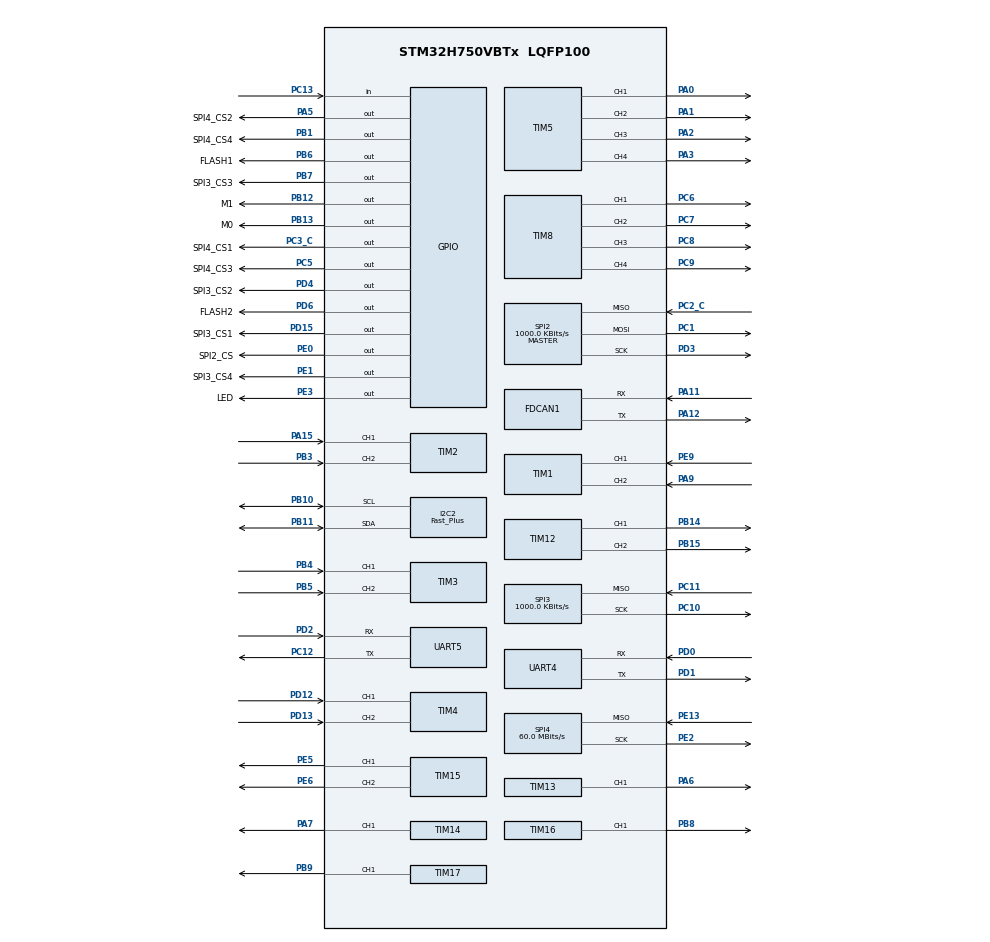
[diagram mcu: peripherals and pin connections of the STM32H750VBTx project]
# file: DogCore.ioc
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CORTEX_M7.default_mode_Activation=1
Dma.Request0=UART4_RX
Dma.Request1=UART4_TX
Dma.Request2=UART5_RX
Dma.Request3=UART5_TX
Dma.UART4_RX.0.Direction=DMA_PERIPH_TO_MEMORY
Dma.UART4_RX.0.EventEnable=DISABLE
Dma.UART4_RX.0.FIFOMode=DMA_FIFOMODE_DISABLE
Dma.UART4_RX.0.Instance=DMA1_Stream0
Dma.UART4_RX.0.MemDataAlignment=DMA_MDATAALIGN_BYTE
Dma.UART4_RX.0.MemInc=DMA_MINC_ENABLE
Dma.UART4_RX.0.Mode=DMA_NORMAL
Dma.UART4_RX.0.PeriphDataAlignment=DMA_PDATAALIGN_BYTE
Dma.UART4_RX.0.PeriphInc=DMA_PINC_DISABLE
Dma.UART4_RX.0.Polarity=HAL_DMAMUX_REQ_GEN_RISING
Dma.UART4_RX.0.Priority=DMA_PRIORITY_LOW
Dma.UART4_RX.0.RequestNumber=1
Dma.UART4_RX.0.SignalID=NONE
Dma.UART4_RX.0.SyncEnable=DISABLE
Dma.UART4_RX.0.SyncPolarity=HAL_DMAMUX_SYNC_NO_EVENT
Dma.UART4_RX.0.SyncRequestNumber=1
Dma.UART4_RX.0.SyncSignalID=NONE
Dma.UART4_TX.1.Direction=DMA_MEMORY_TO_PERIPH
Dma.UART4_TX.1.EventEnable=DISABLE
Dma.UART4_TX.1.FIFOMode=DMA_FIFOMODE_DISABLE
Dma.UART4_TX.1.Instance=DMA1_Stream1
Dma.UART4_TX.1.MemDataAlignment=DMA_MDATAALIGN_BYTE
Dma.UART4_TX.1.MemInc=DMA_MINC_ENABLE
Dma.UART4_TX.1.Mode=DMA_NORMAL
Dma.UART4_TX.1.PeriphDataAlignment=DMA_PDATAALIGN_BYTE
Dma.UART4_TX.1.PeriphInc=DMA_PINC_DISABLE
Dma.UART4_TX.1.Polarity=HAL_DMAMUX_REQ_GEN_RISING
Dma.UART4_TX.1.Priority=DMA_PRIORITY_LOW
Dma.UART4_TX.1.RequestNumber=1
Dma.UART4_TX.1.SignalID=NONE
Dma.UART4_TX.1.SyncEnable=DISABLE
Dma.UART4_TX.1.SyncPolarity=HAL_DMAMUX_SYNC_NO_EVENT
Dma.UART4_TX.1.SyncRequestNumber=1
Dma.UART4_TX.1.SyncSignalID=NONE
Dma.UART5_RX.2.Direction=DMA_PERIPH_TO_MEMORY
Dma.UART5_RX.2.EventEnable=DISABLE
Dma.UART5_RX.2.FIFOMode=DMA_FIFOMODE_DISABLE
Dma.UART5_RX.2.Instance=DMA1_Stream2
Dma.UART5_RX.2.MemDataAlignment=DMA_MDATAALIGN_BYTE
Dma.UART5_RX.2.MemInc=DMA_MINC_ENABLE
Dma.UART5_RX.2.Mode=DMA_NORMAL
Dma.UART5_RX.2.PeriphDataAlignment=DMA_PDATAALIGN_BYTE
Dma.UART5_RX.2.PeriphInc=DMA_PINC_DISABLE
Dma.UART5_RX.2.Polarity=HAL_DMAMUX_REQ_GEN_RISING
Dma.UART5_RX.2.Priority=DMA_PRIORITY_LOW
Dma.UART5_RX.2.RequestNumber=1
Dma.UART5_RX.2.SignalID=NONE
Dma.UART5_RX.2.SyncEnable=DISABLE
Dma.UART5_RX.2.SyncPolarity=HAL_DMAMUX_SYNC_NO_EVENT
Dma.UART5_RX.2.SyncRequestNumber=1
Dma.UART5_RX.2.SyncSignalID=NONE
Dma.UART5_TX.3.Direction=DMA_MEMORY_TO_PERIPH
Dma.UART5_TX.3.EventEnable=DISABLE
Dma.UART5_TX.3.FIFOMode=DMA_FIFOMODE_DISABLE
Dma.UART5_TX.3.Instance=DMA1_Stream3
Dma.UART5_TX.3.MemDataAlignment=DMA_MDATAALIGN_BYTE
Dma.UART5_TX.3.MemInc=DMA_MINC_ENABLE
Dma.UART5_TX.3.Mode=DMA_NORMAL
Dma.UART5_TX.3.PeriphDataAlignment=DMA_PDATAALIGN_BYTE
Dma.UART5_TX.3.PeriphInc=DMA_PINC_DISABLE
Dma.UART5_TX.3.Polarity=HAL_DMAMUX_REQ_GEN_RISING
Dma.UART5_TX.3.Priority=DMA_PRIORITY_LOW
Dma.UART5_TX.3.RequestNumber=1
Dma.UART5_TX.3.SignalID=NONE
Dma.UART5_TX.3.SyncEnable=DISABLE
Dma.UART5_TX.3.SyncPolarity=HAL_DMAMUX_SYNC_NO_EVENT
Dma.UART5_TX.3.SyncRequestNumber=1
Dma.UART5_TX.3.SyncSignalID=NONE
FDCAN1.AutoRetransmission=ENABLE
FDCAN1.CalculateBaudRateNominal=500000
FDCAN1.CalculateTimeBitNominal=2000
FDCAN1.CalculateTimeQuantumNominal=400.0
FDCAN1.NominalPrescaler=10
FDCAN1.NominalSyncJumpWidth=1
FDCAN1.NominalTimeSeg1=3
FDCAN1.NominalTimeSeg2=1
FDCAN1.TxBuffersNbr=32
FREERTOS.BinarySemaphores01=CAN_TX_BS,Static,CAN_TX_BSControlBlock,Available;UART_RX_BS,Static,UART_RX_BSControlBlock,Available
FREERTOS.CountingSemaphores01=UART_TX_CS,16,Static,UART_TX_CSControlBlock,0
FREERTOS.Mutexes01=IIC_LOCK,Static,IIC_LOCKControlBlock
FREERTOS.Queues01=KEY_CMD_Q,16,App_Key_EventPacket_t,0,Static,KEY_CMD_QBuffer,KEY_CMD_QControlBlock;UART_RX_Q,16,uint8_t,0,Static,UART_RX_QBuffer,UART_RX_QControlBlock;UART_TX_Q,16,APP_TxFrame_t,0,Static,UART_TX_QBuffer,UART_TX_QControlBlock;CAN_RXF0_Q,16,BSP_CAN_Packet_t,0,Static,CAN_RXF0_QBuffer,CAN_RXF0_QControlBlock;CAN_RXF1_Q,16,BSP_CAN_Packet_t,0,Static,CAN_RXF1_QBuffer,CAN_RXF1_QControlBlock
FREERTOS.Tasks01=defaultTask,8,128,StartDefaultTask,As weak,NULL,Static,defaultTaskBuffer,defaultTaskControlBlock;KEY_Debounce_T,52,128,Task_KEY_Debounce,As weak,NULL,Static,KEY_Debounce_TBuffer,KEY_Debounce_TControlBlock;KEY_CMD_T,44,128,TASK_KEY_CMD,As weak,NULL,Static,KEY_CMD_TBuffer,KEY_CMD_TControlBlock;UART_RX_T,51,256,Task_UART_RX,As weak,NULL,Static,UART_RX_TBuffer,UART_RX_TControlBlock;UART_TX_T,38,128,Task_UART_TX,As weak,NULL,Static,UART_TX_TBuffer,UART_TX_TControlBlock;UART_RX_CMD,50,128,Task_UART_RX_CMD,As weak,NULL,Static,UART_RX_CMDBuffer,UART_RX_CMDControlBlock;CAN_TX_T,37,128,Task_CAN_TX,As weak,NULL,Static,CAN_TX_TBuffer,CAN_TX_TControlBlock;CAN_RXF0_T,54,256,Task_CAN_RXF0,As weak,NULL,Static,CAN_RXF0_TBuffer,CAN_RXF0_TControlBlock;CAN_RXF1_T,53,256,Task_CAN_RXF1,As weak,NULL,Static,CAN_RXF1_TBuffer,CAN_RXF1_TControlBlock;Servo_T,46,128,Task_Servo,As weak,NULL,Static,Servo_TBuffer,Servo_TControlBlock;OLED_T,14,256,Task_OLED,As weak,NULL,Static,OLED_TBuffer,OLED_TControlBlock;Motion_T,45,256,Task_Motion,As weak,NULL,Static,Motion_TBuffer,Motion_TControlBlock;Motor_T,45,256,Task_Motor,As weak,NULL,Static,Motor_TBuffer,Motor_TControlBlock
FREERTOS.configMINIMAL_STACK_SIZE=64
FREERTOS.configTOTAL_HEAP_SIZE=256
I2C2.I2C_Speed_Mode=I2C_Fast_Plus
I2C2.Timing=0x0050174F
Mcu.Family=STM32H7
Mcu.Name=STM32H750VBTx
Mcu.Package=LQFP100
NVIC.DMA1_Stream0_IRQn=true\:5\:0\:false\:false\:true\:true\:false\:true\:true
NVIC.DMA1_Stream1_IRQn=true\:5\:0\:false\:false\:true\:true\:false\:true\:true
NVIC.DMA1_Stream2_IRQn=true\:5\:0\:false\:false\:true\:true\:false\:true\:true
NVIC.DMA1_Stream3_IRQn=true\:5\:0\:false\:false\:true\:true\:false\:true\:true
NVIC.FDCAN1_IT0_IRQn=true\:5\:0\:false\:false\:true\:true\:true\:true\:true
NVIC.FDCAN1_IT1_IRQn=true\:5\:0\:false\:false\:true\:true\:true\:true\:true
NVIC.PriorityGroup=NVIC_PRIORITYGROUP_4
NVIC.TIM6_DAC_IRQn=true\:15\:0\:false\:false\:true\:false\:false\:true\:true
NVIC.TimeBase=TIM6_DAC_IRQn
NVIC.TimeBaseIP=TIM6
NVIC.UART4_IRQn=true\:5\:0\:false\:false\:true\:true\:true\:true\:true
NVIC.UART5_IRQn=true\:5\:0\:false\:false\:true\:true\:true\:true\:true
PA0.Signal=S_TIM5_CH1
PA1.Signal=S_TIM5_CH2
PA11.Mode=FDCAN_Activate
PA11.Signal=FDCAN1_RX
PA12.Mode=FDCAN_Activate
PA12.Signal=FDCAN1_TX
PA13\ (JTMS/SWDIO).Mode=Serial_Wire
PA13\ (JTMS/SWDIO).Signal=DEBUG_JTMS-SWDIO
PA14\ (JTCK/SWCLK).Mode=Serial_Wire
PA14\ (JTCK/SWCLK).Signal=DEBUG_JTCK-SWCLK
PA15\ (JTDI).Signal=S_TIM2_CH1_ETR
PA2.Signal=S_TIM5_CH3
PA3.Signal=S_TIM5_CH4
PA5.GPIO_Label=SPI4_CS2
PA5.Signal=GPIO_Output
PA6.Signal=S_TIM13_CH1
PA7.Signal=S_TIM14_CH1
PA9.Signal=S_TIM1_CH2
PB1.GPIO_Label=SPI4_CS4
PB1.Signal=GPIO_Output
PB10.Mode=I2C
PB10.Signal=I2C2_SCL
PB11.Mode=I2C
PB11.Signal=I2C2_SDA
PB12.GPIO_Label=M1
PB12.GPIO_PuPd=GPIO_PULLDOWN
PB12.Signal=GPIO_Output
PB13.GPIO_Label=M0
PB13.GPIO_PuPd=GPIO_PULLDOWN
PB13.PinState=GPIO_PIN_RESET
PB13.Signal=GPIO_Output
PB14.Signal=S_TIM12_CH1
PB15.Signal=S_TIM12_CH2
PB3\ (JTDO/TRACESWO).Signal=S_TIM2_CH2
PB4\ (NJTRST).Signal=S_TIM3_CH1
PB5.Signal=S_TIM3_CH2
PB6.GPIO_Label=FLASH1
PB6.Signal=GPIO_Output
PB7.GPIO_Label=SPI3_CS3
PB7.Signal=GPIO_Output
PB8.Signal=S_TIM16_CH1
PB9.Signal=S_TIM17_CH1
PC1.Mode=Full_Duplex_Master
PC1.Signal=SPI2_MOSI
PC10.Mode=RX_Only_Simplex_Unidirect_Master
PC10.Signal=SPI3_SCK
PC11.Mode=RX_Only_Simplex_Unidirect_Master
PC11.Signal=SPI3_MISO
PC12.Mode=Asynchronous
PC12.Signal=UART5_TX
PC13.GPIO_PuPd=GPIO_PULLDOWN
PC13.Signal=GPIO_Input
PC2_C.Mode=Full_Duplex_Master
PC2_C.Signal=SPI2_MISO
PC3_C.GPIO_Label=SPI4_CS1
PC3_C.Signal=GPIO_Output
PC5.GPIO_Label=SPI4_CS3
PC5.Signal=GPIO_Output
PC6.Signal=S_TIM8_CH1
PC7.Signal=S_TIM8_CH2
PC8.Signal=S_TIM8_CH3
PC9.Signal=S_TIM8_CH4
PD0.Mode=Asynchronous
PD0.Signal=UART4_RX
PD1.Mode=Asynchronous
PD1.Signal=UART4_TX
PD12.Signal=S_TIM4_CH1
PD13.Signal=S_TIM4_CH2
PD15.GPIO_Label=SPI3_CS1
PD15.Signal=GPIO_Output
PD2.Mode=Asynchronous
PD2.Signal=UART5_RX
PD3.Mode=Full_Duplex_Master
PD3.Signal=SPI2_SCK
PD4.GPIO_Label=SPI3_CS2
PD4.Signal=GPIO_Output
PD6.GPIO_Label=FLASH2
PD6.Signal=GPIO_Output
PE0.GPIO_Label=SPI2_CS
PE0.Signal=GPIO_Output
PE1.GPIO_Label=SPI3_CS4
PE1.Signal=GPIO_Output
PE13.Mode=RX_Only_Simplex_Unidirect_Master
PE13.Signal=SPI4_MISO
PE2.Mode=RX_Only_Simplex_Unidirect_Master
PE2.Signal=SPI4_SCK
PE3.GPIO_Label=LED
PE3.Signal=GPIO_Output
PE5.Signal=S_TIM15_CH1
PE6.Signal=S_TIM15_CH2
PE9.Signal=S_TIM1_CH1
PH0-OSC_IN\ (PH0).Mode=HSE-External-Oscillator
PH0-OSC_IN\ (PH0).Signal=RCC_OSC_IN
PH1-OSC_OUT\ (PH1).Mode=HSE-External-Oscillator
PH1-OSC_OUT\ (PH1).Signal=RCC_OSC_OUT
ProjectManager.HeapSize=0x200
ProjectManager.StackSize=0x400
ProjectManager.TargetToolchain=CMake
RCC.ADCFreq_Value=50390625
RCC.APB1Freq_Value=120000000
RCC.APB2Freq_Value=120000000
RCC.APB3Freq_Value=120000000
RCC.APB4Freq_Value=120000000
RCC.CortexFreq_Value=480000000
RCC.D1PPRE=RCC_APB3_DIV2
RCC.D2PPRE1=RCC_APB1_DIV2
RCC.D2PPRE2=RCC_APB2_DIV2
RCC.D3PPRE=RCC_APB4_DIV2
RCC.DIVM1=5
RCC.DIVN1=192
RCC.DIVQ1=3
RCC.FDCANCLockSelection=RCC_FDCANCLKSOURCE_HSE
RCC.HCLKFreq_Value=240000000
RCC.HPRE=RCC_HCLK_DIV2
RCC.PLL2FRACN=0
RCC.PLL3FRACN=0
RCC.PLLFRACN=0
RCC.PLLSourceVirtual=RCC_PLLSOURCE_HSE
RCC.SPI123CLockSelection=RCC_SPI123CLKSOURCE_CLKP
RCC.SYSCLKFreq_VALUE=480000000
RCC.SYSCLKSource=RCC_SYSCLKSOURCE_PLLCLK
RCC.USBFreq_Value=320000000
SH.S_TIM12_CH1.0=TIM12_CH1,PWM Generation1 CH1
SH.S_TIM12_CH2.0=TIM12_CH2,PWM Generation2 CH2
SH.S_TIM13_CH1.0=TIM13_CH1,PWM Generation1 CH1
SH.S_TIM14_CH1.0=TIM14_CH1,PWM Generation1 CH1
SH.S_TIM15_CH1.0=TIM15_CH1,PWM Generation1 CH1
SH.S_TIM15_CH2.0=TIM15_CH2,PWM Generation2 CH2
SH.S_TIM16_CH1.0=TIM16_CH1,PWM Generation1 CH1
SH.S_TIM17_CH1.0=TIM17_CH1,PWM Generation1 CH1
SH.S_TIM1_CH1.0=TIM1_CH1,Encoder_Interface
SH.S_TIM1_CH2.0=TIM1_CH2,Encoder_Interface
SH.S_TIM2_CH1_ETR.0=TIM2_CH1,Encoder_Interface
SH.S_TIM2_CH2.0=TIM2_CH2,Encoder_Interface
SH.S_TIM3_CH1.0=TIM3_CH1,Encoder_Interface
SH.S_TIM3_CH2.0=TIM3_CH2,Encoder_Interface
SH.S_TIM4_CH1.0=TIM4_CH1,Encoder_Interface
SH.S_TIM4_CH2.0=TIM4_CH2,Encoder_Interface
SH.S_TIM5_CH1.0=TIM5_CH1,PWM Generation1 CH1
SH.S_TIM5_CH2.0=TIM5_CH2,PWM Generation2 CH2
SH.S_TIM5_CH3.0=TIM5_CH3,PWM Generation3 CH3
SH.S_TIM5_CH4.0=TIM5_CH4,PWM Generation4 CH4
SH.S_TIM8_CH1.0=TIM8_CH1,PWM Generation1 CH1
SH.S_TIM8_CH2.0=TIM8_CH2,PWM Generation2 CH2
SH.S_TIM8_CH3.0=TIM8_CH3,PWM Generation3 CH3
SH.S_TIM8_CH4.0=TIM8_CH4,PWM Generation4 CH4
SPI2.BaudRatePrescaler=SPI_BAUDRATEPRESCALER_64
SPI2.CalculateBaudRate=1000.0 KBits/s
SPI2.Direction=SPI_DIRECTION_2LINES
SPI2.Mode=SPI_MODE_MASTER
SPI2.VirtualType=VM_MASTER
SPI3.BaudRatePrescaler=SPI_BAUDRATEPRESCALER_64
SPI3.CalculateBaudRate=1000.0 KBits/s
SPI3.Direction=SPI_DIRECTION_2LINES_RXONLY
SPI3.Mode=SPI_MODE_MASTER
SPI3.VirtualType=VM_MASTER
SPI4.CalculateBaudRate=60.0 MBits/s
SPI4.Direction=SPI_DIRECTION_2LINES_RXONLY
SPI4.Mode=SPI_MODE_MASTER
SPI4.VirtualType=VM_MASTER
TIM1.EncoderMode=TIM_ENCODERMODE_TI12
TIM1.IC1Filter=10
TIM1.IC2Filter=10
TIM12.Channel-PWM\ Generation1\ CH1=TIM_CHANNEL_1
TIM12.Channel-PWM\ Generation2\ CH2=TIM_CHANNEL_2
TIM13.Channel=TIM_CHANNEL_1
TIM14.Channel=TIM_CHANNEL_1
TIM15.Channel-PWM\ Generation1\ CH1=TIM_CHANNEL_1
TIM15.Channel-PWM\ Generation2\ CH2=TIM_CHANNEL_2
TIM16.Channel=TIM_CHANNEL_1
TIM17.Channel=TIM_CHANNEL_1
TIM2.EncoderMode=TIM_ENCODERMODE_TI12
TIM2.IC1Filter=10
TIM2.IC2Filter=10
TIM3.EncoderMode=TIM_ENCODERMODE_TI12
TIM3.IC1Filter=10
TIM3.IC2Filter=10
TIM4.EncoderMode=TIM_ENCODERMODE_TI12
TIM4.IC1Filter=10
TIM4.IC2Filter=10
TIM5.Channel-PWM\ Generation1\ CH1=TIM_CHANNEL_1
TIM5.Channel-PWM\ Generation2\ CH2=TIM_CHANNEL_2
TIM5.Channel-PWM\ Generation3\ CH3=TIM_CHANNEL_3
TIM5.Channel-PWM\ Generation4\ CH4=TIM_CHANNEL_4
TIM8.Channel-PWM\ Generation1\ CH1=TIM_CHANNEL_1
TIM8.Channel-PWM\ Generation2\ CH2=TIM_CHANNEL_2
TIM8.Channel-PWM\ Generation3\ CH3=TIM_CHANNEL_3
TIM8.Channel-PWM\ Generation4\ CH4=TIM_CHANNEL_4
VP_FREERTOS_VS_CMSIS_V2.Mode=CMSIS_V2
VP_MEMORYMAP_VS_MEMORYMAP.Mode=CurAppReg
VP_SYS_VS_tim6.Mode=TIM6
VP_TIM12_VS_ClockSourceINT.Mode=Internal
VP_TIM13_VS_ClockSourceINT.Mode=Enable_Timer
VP_TIM14_VS_ClockSourceINT.Mode=Enable_Timer
VP_TIM15_VS_ClockSourceINT.Mode=Internal
VP_TIM16_VS_ClockSourceINT.Mode=Enable_Timer
VP_TIM17_VS_ClockSourceINT.Mode=Enable_Timer
VP_TIM5_VS_ClockSourceINT.Mode=Internal
VP_TIM8_VS_ClockSourceINT.Mode=Internal
board=custom

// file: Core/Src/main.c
/* USER CODE BEGIN Header */
/**
  ******************************************************************************
  * @file           : main.c
  * @brief          : Main program body
  ******************************************************************************
  * @attention
  *
  * Copyright (c) 2026 STMicroelectronics.
  * All rights reserved.
  *
  * This software is licensed under terms that can be found in the LICENSE file
  * in the root directory of this software component.
  * If no LICENSE file comes with this software, it is provided AS-IS.
  *
  ******************************************************************************
  */
/* USER CODE END Header */
#include "main.h"
#include "cmsis_os.h"
#include "dma.h"
#include "fdcan.h"
#include "i2c.h"
#include "spi.h"
#include "tim.h"
#include "usart.h"
#include "gpio.h"

void SystemClock_Config(void);
void PeriphCommonClock_Config(void);
static void MPU_Config(void);
void MX_FREERTOS_Init(void);

int main(void)
{

  /* MPU Configuration--------------------------------------------------------*/
  MPU_Config();

  /* MCU Configuration--------------------------------------------------------*/

  /* Reset of all peripherals, Initializes the Flash interface and the Systick. */
  HAL_Init();

  /* Configure the system clock */
  SystemClock_Config();

  /* Configure the peripherals common clocks */
  PeriphCommonClock_Config();

  /* Initialize all configured peripherals */
  MX_GPIO_Init();
  MX_DMA_Init();
  MX_TIM1_Init();
  MX_FDCAN1_Init();
  MX_TIM2_Init();
  MX_TIM3_Init();
  MX_TIM4_Init();
  MX_TIM5_Init();
  MX_TIM8_Init();
  MX_TIM12_Init();
  MX_TIM13_Init();
  MX_TIM14_Init();
  MX_TIM15_Init();
  MX_TIM16_Init();
  MX_TIM17_Init();
  MX_I2C2_Init();
  MX_SPI2_Init();
  MX_SPI3_Init();
  MX_SPI4_Init();
  MX_UART4_Init();
  MX_UART5_Init();

  /* Init scheduler */
  osKernelInitialize();  /* Call init function for freertos objects (in cmsis_os2.c) */
  MX_FREERTOS_Init();

  /* Start scheduler */
  osKernelStart();

  /* We should never get here as control is now taken by the scheduler */

  /* Infinite loop */
  while (1)
  {

  }
}

void SystemClock_Config(void)
{
  RCC_OscInitTypeDef RCC_OscInitStruct = {0};
  RCC_ClkInitTypeDef RCC_ClkInitStruct = {0};

  /** Supply configuration update enable
  */
  HAL_PWREx_ConfigSupply(PWR_LDO_SUPPLY);

  /** Configure the main internal regulator output voltage
  */
  __HAL_PWR_VOLTAGESCALING_CONFIG(PWR_REGULATOR_VOLTAGE_SCALE0);

  while(!__HAL_PWR_GET_FLAG(PWR_FLAG_VOSRDY)) {}

  /** Initializes the RCC Oscillators according to the specified parameters
  * in the RCC_OscInitTypeDef structure.
  */
  RCC_OscInitStruct.OscillatorType = RCC_OSCILLATORTYPE_HSI|RCC_OSCILLATORTYPE_HSE;
  RCC_OscInitStruct.HSEState = RCC_HSE_ON;
  RCC_OscInitStruct.HSIState = RCC_HSI_DIV1;
  RCC_OscInitStruct.HSICalibrationValue = RCC_HSICALIBRATION_DEFAULT;
  RCC_OscInitStruct.PLL.PLLState = RCC_PLL_ON;
  RCC_OscInitStruct.PLL.PLLSource = RCC_PLLSOURCE_HSE;
  RCC_OscInitStruct.PLL.PLLM = 5;
  RCC_OscInitStruct.PLL.PLLN = 192;
  RCC_OscInitStruct.PLL.PLLP = 2;
  RCC_OscInitStruct.PLL.PLLQ = 3;
  RCC_OscInitStruct.PLL.PLLR = 2;
  RCC_OscInitStruct.PLL.PLLRGE = RCC_PLL1VCIRANGE_2;
  RCC_OscInitStruct.PLL.PLLVCOSEL = RCC_PLL1VCOWIDE;
  RCC_OscInitStruct.PLL.PLLFRACN = 0;
  if (HAL_RCC_OscConfig(&RCC_OscInitStruct) != HAL_OK)
  {
    Error_Handler();
  }

  /** Initializes the CPU, AHB and APB buses clocks
  */
  RCC_ClkInitStruct.ClockType = RCC_CLOCKTYPE_HCLK|RCC_CLOCKTYPE_SYSCLK
                              |RCC_CLOCKTYPE_PCLK1|RCC_CLOCKTYPE_PCLK2
                              |RCC_CLOCKTYPE_D3PCLK1|RCC_CLOCKTYPE_D1PCLK1;
  RCC_ClkInitStruct.SYSCLKSource = RCC_SYSCLKSOURCE_PLLCLK;
  RCC_ClkInitStruct.SYSCLKDivider = RCC_SYSCLK_DIV1;
  RCC_ClkInitStruct.AHBCLKDivider = RCC_HCLK_DIV2;
  RCC_ClkInitStruct.APB3CLKDivider = RCC_APB3_DIV2;
  RCC_ClkInitStruct.APB1CLKDivider = RCC_APB1_DIV2;
  RCC_ClkInitStruct.APB2CLKDivider = RCC_APB2_DIV2;
  RCC_ClkInitStruct.APB4CLKDivider = RCC_APB4_DIV2;

  if (HAL_RCC_ClockConfig(&RCC_ClkInitStruct, FLASH_LATENCY_4) != HAL_OK)
  {
    Error_Handler();
  }
}

void PeriphCommonClock_Config(void)
{
  RCC_PeriphCLKInitTypeDef PeriphClkInitStruct = {0};

  /** Initializes the peripherals clock
  */
  PeriphClkInitStruct.PeriphClockSelection = RCC_PERIPHCLK_CKPER;
  PeriphClkInitStruct.CkperClockSelection = RCC_CLKPSOURCE_HSI;
  if (HAL_RCCEx_PeriphCLKConfig(&PeriphClkInitStruct) != HAL_OK)
  {
    Error_Handler();
  }
}

 /* MPU Configuration */

void MPU_Config(void)
{
  MPU_Region_InitTypeDef MPU_InitStruct = {0};

  /* Disables the MPU */
  HAL_MPU_Disable();

  /** Initializes and configures the Region and the memory to be protected
  */
  MPU_InitStruct.Enable = MPU_REGION_ENABLE;
  MPU_InitStruct.Number = MPU_REGION_NUMBER0;
  MPU_InitStruct.BaseAddress = 0x0;
  MPU_InitStruct.Size = MPU_REGION_SIZE_4GB;
  MPU_InitStruct.SubRegionDisable = 0x87;
  MPU_InitStruct.TypeExtField = MPU_TEX_LEVEL0;
  MPU_InitStruct.AccessPermission = MPU_REGION_NO_ACCESS;
  MPU_InitStruct.DisableExec = MPU_INSTRUCTION_ACCESS_DISABLE;
  MPU_InitStruct.IsShareable = MPU_ACCESS_SHAREABLE;
  MPU_InitStruct.IsCacheable = MPU_ACCESS_NOT_CACHEABLE;
  MPU_InitStruct.IsBufferable = MPU_ACCESS_NOT_BUFFERABLE;

  HAL_MPU_ConfigRegion(&MPU_InitStruct);
  /* Enables the MPU */
  HAL_MPU_Enable(MPU_PRIVILEGED_DEFAULT);

}

void HAL_TIM_PeriodElapsedCallback(TIM_HandleTypeDef *htim)
{
  if (htim->Instance == TIM6)
  {
    HAL_IncTick();
  }
}

void Error_Handler(void)
{
  __disable_irq();
  while (1)
  {
  }
}

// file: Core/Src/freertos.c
/* USER CODE BEGIN Header */
/**
  ******************************************************************************
  * File Name          : freertos.c
  * Description        : Code for freertos applications
  ******************************************************************************
  * @attention
  *
  * Copyright (c) 2026 STMicroelectronics.
  * All rights reserved.
  *
  * This software is licensed under terms that can be found in the LICENSE file
  * in the root directory of this software component.
  * If no LICENSE file comes with this software, it is provided AS-IS.
  *
  ******************************************************************************
  */
/* USER CODE END Header */

#include "FreeRTOS.h"
#include "task.h"
#include "main.h"
#include "cmsis_os.h"

/* USER CODE BEGIN Includes */
#include "app_key.h"
#include "bsp_can.h"
#include "app_uart.h"
#include "app_motor_debug.h"
/* USER CODE END Includes */

typedef StaticTask_t osStaticThreadDef_t;
typedef StaticQueue_t osStaticMessageQDef_t;
typedef StaticSemaphore_t osStaticSemaphoreDef_t;

/* Definitions for defaultTask */
osThreadId_t defaultTaskHandle;
uint32_t defaultTaskBuffer[ 128 ];
osStaticThreadDef_t defaultTaskControlBlock;
const osThreadAttr_t defaultTask_attributes = {
  .name = "defaultTask",
  .cb_mem = &defaultTaskControlBlock,
  .cb_size = sizeof(defaultTaskControlBlock),
  .stack_mem = &defaultTaskBuffer[0],
  .stack_size = sizeof(defaultTaskBuffer),
  .priority = (osPriority_t) osPriorityLow,
};
/* Definitions for KEY_Debounce_T */
osThreadId_t KEY_Debounce_THandle;
uint32_t KEY_Debounce_TBuffer[ 128 ];
osStaticThreadDef_t KEY_Debounce_TControlBlock;
const osThreadAttr_t KEY_Debounce_T_attributes = {
  .name = "KEY_Debounce_T",
  .cb_mem = &KEY_Debounce_TControlBlock,
  .cb_size = sizeof(KEY_Debounce_TControlBlock),
  .stack_mem = &KEY_Debounce_TBuffer[0],
  .stack_size = sizeof(KEY_Debounce_TBuffer),
  .priority = (osPriority_t) osPriorityRealtime4,
};
/* Definitions for KEY_CMD_T */
osThreadId_t KEY_CMD_THandle;
uint32_t KEY_CMD_TBuffer[ 128 ];
osStaticThreadDef_t KEY_CMD_TControlBlock;
const osThreadAttr_t KEY_CMD_T_attributes = {
  .name = "KEY_CMD_T",
  .cb_mem = &KEY_CMD_TControlBlock,
  .cb_size = sizeof(KEY_CMD_TControlBlock),
  .stack_mem = &KEY_CMD_TBuffer[0],
  .stack_size = sizeof(KEY_CMD_TBuffer),
  .priority = (osPriority_t) osPriorityHigh4,
};
/* Definitions for UART_RX_T */
osThreadId_t UART_RX_THandle;
uint32_t UART_RX_TBuffer[ 256 ];
osStaticThreadDef_t UART_RX_TControlBlock;
const osThreadAttr_t UART_RX_T_attributes = {
  .name = "UART_RX_T",
  .cb_mem = &UART_RX_TControlBlock,
  .cb_size = sizeof(UART_RX_TControlBlock),
  .stack_mem = &UART_RX_TBuffer[0],
  .stack_size = sizeof(UART_RX_TBuffer),
  .priority = (osPriority_t) osPriorityRealtime3,
};
/* Definitions for UART_TX_T */
osThreadId_t UART_TX_THandle;
uint32_t UART_TX_TBuffer[ 128 ];
osStaticThreadDef_t UART_TX_TControlBlock;
const osThreadAttr_t UART_TX_T_attributes = {
  .name = "UART_TX_T",
  .cb_mem = &UART_TX_TControlBlock,
  .cb_size = sizeof(UART_TX_TControlBlock),
  .stack_mem = &UART_TX_TBuffer[0],
  .stack_size = sizeof(UART_TX_TBuffer),
  .priority = (osPriority_t) osPriorityAboveNormal6,
};
/* Definitions for UART_RX_CMD */
osThreadId_t UART_RX_CMDHandle;
uint32_t UART_RX_CMDBuffer[ 128 ];
osStaticThreadDef_t UART_RX_CMDControlBlock;
const osThreadAttr_t UART_RX_CMD_attributes = {
  .name = "UART_RX_CMD",
  .cb_mem = &UART_RX_CMDControlBlock,
  .cb_size = sizeof(UART_RX_CMDControlBlock),
  .stack_mem = &UART_RX_CMDBuffer[0],
  .stack_size = sizeof(UART_RX_CMDBuffer),
  .priority = (osPriority_t) osPriorityRealtime2,
};
/* Definitions for CAN_TX_T */
osThreadId_t CAN_TX_THandle;
uint32_t CAN_TX_TBuffer[ 128 ];
osStaticThreadDef_t CAN_TX_TControlBlock;
const osThreadAttr_t CAN_TX_T_attributes = {
  .name = "CAN_TX_T",
  .cb_mem = &CAN_TX_TControlBlock,
  .cb_size = sizeof(CAN_TX_TControlBlock),
  .stack_mem = &CAN_TX_TBuffer[0],
  .stack_size = sizeof(CAN_TX_TBuffer),
  .priority = (osPriority_t) osPriorityAboveNormal5,
};
/* Definitions for CAN_RXF0_T */
osThreadId_t CAN_RXF0_THandle;
uint32_t CAN_RXF0_TBuffer[ 256 ];
osStaticThreadDef_t CAN_RXF0_TControlBlock;
const osThreadAttr_t CAN_RXF0_T_attributes = {
  .name = "CAN_RXF0_T",
  .cb_mem = &CAN_RXF0_TControlBlock,
  .cb_size = sizeof(CAN_RXF0_TControlBlock),
  .stack_mem = &CAN_RXF0_TBuffer[0],
  .stack_size = sizeof(CAN_RXF0_TBuffer),
  .priority = (osPriority_t) osPriorityRealtime6,
};
/* Definitions for CAN_RXF1_T */
osThreadId_t CAN_RXF1_THandle;
uint32_t CAN_RXF1_TBuffer[ 256 ];
osStaticThreadDef_t CAN_RXF1_TControlBlock;
const osThreadAttr_t CAN_RXF1_T_attributes = {
  .name = "CAN_RXF1_T",
  .cb_mem = &CAN_RXF1_TControlBlock,
  .cb_size = sizeof(CAN_RXF1_TControlBlock),
  .stack_mem = &CAN_RXF1_TBuffer[0],
  .stack_size = sizeof(CAN_RXF1_TBuffer),
  .priority = (osPriority_t) osPriorityRealtime5,
};
/* Definitions for Servo_T */
osThreadId_t Servo_THandle;
uint32_t Servo_TBuffer[ 128 ];
osStaticThreadDef_t Servo_TControlBlock;
const osThreadAttr_t Servo_T_attributes = {
  .name = "Servo_T",
  .cb_mem = &Servo_TControlBlock,
  .cb_size = sizeof(Servo_TControlBlock),
  .stack_mem = &Servo_TBuffer[0],
  .stack_size = sizeof(Servo_TBuffer),
  .priority = (osPriority_t) osPriorityHigh6,
};
/* Definitions for OLED_T */
osThreadId_t OLED_THandle;
uint32_t OLED_TBuffer[ 256 ];
osStaticThreadDef_t OLED_TControlBlock;
const osThreadAttr_t OLED_T_attributes = {
  .name = "OLED_T",
  .cb_mem = &OLED_TControlBlock,
  .cb_size = sizeof(OLED_TControlBlock),
  .stack_mem = &OLED_TBuffer[0],
  .stack_size = sizeof(OLED_TBuffer),
  .priority = (osPriority_t) osPriorityLow6,
};
/* Definitions for Motion_T */
osThreadId_t Motion_THandle;
uint32_t Motion_TBuffer[ 256 ];
osStaticThreadDef_t Motion_TControlBlock;
const osThreadAttr_t Motion_T_attributes = {
  .name = "Motion_T",
  .cb_mem = &Motion_TControlBlock,
  .cb_size = sizeof(Motion_TControlBlock),
  .stack_mem = &Motion_TBuffer[0],
  .stack_size = sizeof(Motion_TBuffer),
  .priority = (osPriority_t) osPriorityHigh5,
};
/* Definitions for Motor_T */
osThreadId_t Motor_THandle;
uint32_t Motor_TBuffer[ 256 ];
osStaticThreadDef_t Motor_TControlBlock;
const osThreadAttr_t Motor_T_attributes = {
  .name = "Motor_T",
  .cb_mem = &Motor_TControlBlock,
  .cb_size = sizeof(Motor_TControlBlock),
  .stack_mem = &Motor_TBuffer[0],
  .stack_size = sizeof(Motor_TBuffer),
  .priority = (osPriority_t) osPriorityHigh5,
};
/* Definitions for KEY_CMD_Q */
osMessageQueueId_t KEY_CMD_QHandle;
uint8_t KEY_CMD_QBuffer[ 16 * sizeof( App_Key_EventPacket_t ) ];
osStaticMessageQDef_t KEY_CMD_QControlBlock;
const osMessageQueueAttr_t KEY_CMD_Q_attributes = {
  .name = "KEY_CMD_Q",
  .cb_mem = &KEY_CMD_QControlBlock,
  .cb_size = sizeof(KEY_CMD_QControlBlock),
  .mq_mem = &KEY_CMD_QBuffer,
  .mq_size = sizeof(KEY_CMD_QBuffer)
};
/* Definitions for UART_RX_Q */
osMessageQueueId_t UART_RX_QHandle;
uint8_t UART_RX_QBuffer[ 16 * sizeof( uint8_t ) ];
osStaticMessageQDef_t UART_RX_QControlBlock;
const osMessageQueueAttr_t UART_RX_Q_attributes = {
  .name = "UART_RX_Q",
  .cb_mem = &UART_RX_QControlBlock,
  .cb_size = sizeof(UART_RX_QControlBlock),
  .mq_mem = &UART_RX_QBuffer,
  .mq_size = sizeof(UART_RX_QBuffer)
};
/* Definitions for UART_TX_Q */
osMessageQueueId_t UART_TX_QHandle;
uint8_t UART_TX_QBuffer[ 16 * sizeof( APP_TxFrame_t ) ];
osStaticMessageQDef_t UART_TX_QControlBlock;
const osMessageQueueAttr_t UART_TX_Q_attributes = {
  .name = "UART_TX_Q",
  .cb_mem = &UART_TX_QControlBlock,
  .cb_size = sizeof(UART_TX_QControlBlock),
  .mq_mem = &UART_TX_QBuffer,
  .mq_size = sizeof(UART_TX_QBuffer)
};
/* Definitions for CAN_RXF0_Q */
osMessageQueueId_t CAN_RXF0_QHandle;
uint8_t CAN_RXF0_QBuffer[ 16 * sizeof( BSP_CAN_Packet_t ) ];
osStaticMessageQDef_t CAN_RXF0_QControlBlock;
const osMessageQueueAttr_t CAN_RXF0_Q_attributes = {
  .name = "CAN_RXF0_Q",
  .cb_mem = &CAN_RXF0_QControlBlock,
  .cb_size = sizeof(CAN_RXF0_QControlBlock),
  .mq_mem = &CAN_RXF0_QBuffer,
  .mq_size = sizeof(CAN_RXF0_QBuffer)
};
/* Definitions for CAN_RXF1_Q */
osMessageQueueId_t CAN_RXF1_QHandle;
uint8_t CAN_RXF1_QBuffer[ 16 * sizeof( BSP_CAN_Packet_t ) ];
osStaticMessageQDef_t CAN_RXF1_QControlBlock;
const osMessageQueueAttr_t CAN_RXF1_Q_attributes = {
  .name = "CAN_RXF1_Q",
  .cb_mem = &CAN_RXF1_QControlBlock,
  .cb_size = sizeof(CAN_RXF1_QControlBlock),
  .mq_mem = &CAN_RXF1_QBuffer,
  .mq_size = sizeof(CAN_RXF1_QBuffer)
};
/* Definitions for CAN_TX_BS */
osSemaphoreId_t CAN_TX_BSHandle;
osStaticSemaphoreDef_t CAN_TX_BSControlBlock;
const osSemaphoreAttr_t CAN_TX_BS_attributes = {
  .name = "CAN_TX_BS",
  .cb_mem = &CAN_TX_BSControlBlock,
  .cb_size = sizeof(CAN_TX_BSControlBlock),
};
/* Definitions for UART_RX_BS */
osSemaphoreId_t UART_RX_BSHandle;
osStaticSemaphoreDef_t UART_RX_BSControlBlock;
const osSemaphoreAttr_t UART_RX_BS_attributes = {
  .name = "UART_RX_BS",
  .cb_mem = &UART_RX_BSControlBlock,
  .cb_size = sizeof(UART_RX_BSControlBlock),
};
/* Definitions for UART_TX_CS */
osSemaphoreId_t UART_TX_CSHandle;
osStaticSemaphoreDef_t UART_TX_CSControlBlock;
const osSemaphoreAttr_t UART_TX_CS_attributes = {
  .name = "UART_TX_CS",
  .cb_mem = &UART_TX_CSControlBlock,
  .cb_size = sizeof(UART_TX_CSControlBlock),
};

void StartDefaultTask(void *argument);
void Task_KEY_Debounce(void *argument);
void TASK_KEY_CMD(void *argument);
void Task_UART_RX(void *argument);
void Task_UART_TX(void *argument);
void Task_UART_RX_CMD(void *argument);
void Task_CAN_TX(void *argument);
void Task_CAN_RXF0(void *argument);
void Task_CAN_RXF1(void *argument);
void Task_Servo(void *argument);
void Task_OLED(void *argument);
void Task_Motion(void *argument);
void Task_Motor(void *argument);

void MX_FREERTOS_Init(void); /* (MISRA C 2004 rule 8.1) */

void MX_FREERTOS_Init(void) {

  /* Create the semaphores(s) */
  /* creation of CAN_TX_BS */
  CAN_TX_BSHandle = osSemaphoreNew(1, 1, &CAN_TX_BS_attributes);

  /* creation of UART_RX_BS */
  UART_RX_BSHandle = osSemaphoreNew(1, 1, &UART_RX_BS_attributes);

  /* creation of UART_TX_CS */
  UART_TX_CSHandle = osSemaphoreNew(16, 0, &UART_TX_CS_attributes);

  /* Create the queue(s) */
  /* creation of KEY_CMD_Q */
  KEY_CMD_QHandle = osMessageQueueNew (16, sizeof(App_Key_EventPacket_t), &KEY_CMD_Q_attributes);

  /* creation of UART_RX_Q */
  UART_RX_QHandle = osMessageQueueNew (16, sizeof(uint8_t), &UART_RX_Q_attributes);

  /* creation of UART_TX_Q */
  UART_TX_QHandle = osMessageQueueNew (16, sizeof(APP_TxFrame_t), &UART_TX_Q_attributes);

  /* creation of CAN_RXF0_Q */
  CAN_RXF0_QHandle = osMessageQueueNew (16, sizeof(BSP_CAN_Packet_t), &CAN_RXF0_Q_attributes);

  /* creation of CAN_RXF1_Q */
  CAN_RXF1_QHandle = osMessageQueueNew (16, sizeof(BSP_CAN_Packet_t), &CAN_RXF1_Q_attributes);

  /* Create the thread(s) */
  /* creation of defaultTask */
  defaultTaskHandle = osThreadNew(StartDefaultTask, NULL, &defaultTask_attributes);

  /* creation of KEY_Debounce_T */
  KEY_Debounce_THandle = osThreadNew(Task_KEY_Debounce, NULL, &KEY_Debounce_T_attributes);

  /* creation of KEY_CMD_T */
  KEY_CMD_THandle = osThreadNew(TASK_KEY_CMD, NULL, &KEY_CMD_T_attributes);

  /* creation of UART_RX_T */
  UART_RX_THandle = osThreadNew(Task_UART_RX, NULL, &UART_RX_T_attributes);

  /* creation of UART_TX_T */
  UART_TX_THandle = osThreadNew(Task_UART_TX, NULL, &UART_TX_T_attributes);

  /* creation of UART_RX_CMD */
  UART_RX_CMDHandle = osThreadNew(Task_UART_RX_CMD, NULL, &UART_RX_CMD_attributes);

  /* creation of CAN_TX_T */
  CAN_TX_THandle = osThreadNew(Task_CAN_TX, NULL, &CAN_TX_T_attributes);

  /* creation of CAN_RXF0_T */
  CAN_RXF0_THandle = osThreadNew(Task_CAN_RXF0, NULL, &CAN_RXF0_T_attributes);

  /* creation of CAN_RXF1_T */
  CAN_RXF1_THandle = osThreadNew(Task_CAN_RXF1, NULL, &CAN_RXF1_T_attributes);

  /* creation of Servo_T */
  Servo_THandle = osThreadNew(Task_Servo, NULL, &Servo_T_attributes);

  /* creation of OLED_T */
  OLED_THandle = osThreadNew(Task_OLED, NULL, &OLED_T_attributes);

  /* creation of Motion_T */
  Motion_THandle = osThreadNew(Task_Motion, NULL, &Motion_T_attributes);

  /* creation of Motor_T */
  Motor_THandle = osThreadNew(Task_Motor, NULL, &Motor_T_attributes);

}

__weak void StartDefaultTask(void *argument)
{
  /* USER CODE BEGIN StartDefaultTask */
  /* Infinite loop */
  for(;;)
  {
    /* 标定完成后取消注释，恢复 PID 调参数据发送 */
    //APP_Motor_SendPIDData(2);
    osDelay(50);
  }
  /* USER CODE END StartDefaultTask */
}

__weak void Task_KEY_Debounce(void *argument)
{
  for(;;)
  {
    osDelay(1);
  }
}

__weak void TASK_KEY_CMD(void *argument)
{
  for(;;)
  {
    osDelay(1);
  }
}

__weak void Task_UART_RX(void *argument)
{
  for(;;)
  {
    osDelay(1);
  }
}

__weak void Task_UART_TX(void *argument)
{
  for(;;)
  {
    osDelay(1);
  }
}

__weak void Task_UART_RX_CMD(void *argument)
{
  for(;;)
  {
    osDelay(1);
  }
}

__weak void Task_CAN_TX(void *argument)
{
  for(;;)
  {
    osDelay(1);
  }
}

__weak void Task_CAN_RXF0(void *argument)
{
  for(;;)
  {
    osDelay(1);
  }
}

__weak void Task_CAN_RXF1(void *argument)
{
  for(;;)
  {
    osDelay(1);
  }
}

__weak void Task_Servo(void *argument)
{
  for(;;)
  {
    osDelay(1);
  }
}

__weak void Task_OLED(void *argument)
{
  for(;;)
  {
    osDelay(1);
  }
}

__weak void Task_Motion(void *argument)
{
  for(;;)
  {
    osDelay(1);
  }
}

__weak void Task_Motor(void *argument)
{
  for(;;)
  {
    osDelay(1);
  }
}
